# earlgrey register map
Vendor: lowRISC; File version: 0.1
CPU: ibex rev01, little endian, no MPU, no FPU, VTOR, 2 interrupt priority bits, 2 interrupts
Registers are 32-bit, read-write, no defined reset value unless marked. A register's access mark holds for its fields unless they carry their own. Offsets are from the block's base; [hi:lo] are bit positions; {n}, {i} and the like mark numbered series.

## SRAM_CTRL_RET_AON — Interfacing on-chip SRAM blocks with system bus, supports lightweight scrambling, integrity and secure wipe
Base 0x40500000
Same registers: SRAM_CTRL_MAIN 0x411C0000
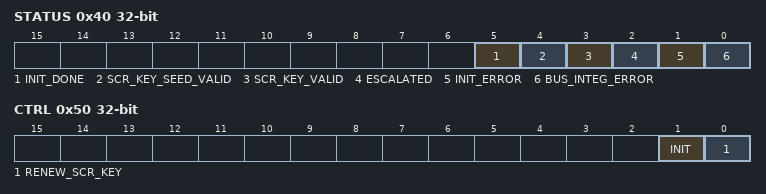
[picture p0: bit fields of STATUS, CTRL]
0x40 STATUS ro — SRAM status register.
  [5] INIT_DONE — Set to 1 if the hardware initialization triggered via !!CTRL.INIT has completed.
  [4] SCR_KEY_SEED_VALID — Set to 1 if the scrambling key has been derived from a valid key seed in OTP.If !!STATUS.SCR_KEY_VALID is set to 1, !!STATUS.SCR_KEY_SEED_VALID should be 1except for cases where the scrambling key seeds have not yet been provisioned toOTP. In such a case, the scrambling key is still ephemeral (i.e., it is derivedusing entropy from CSRNG), but a default all-zero value is used as the key seed.
  [3] SCR_KEY_VALID — Set to 1 if a new scrambling key has been successfully obtained from OTP.Note that if this is set to 0, the SRAM contents are still scrambled, but adefault all-zero key and nonce are used to do so.
  [2] ESCALATED — Set to 1 if the sram controller has received an escalate request.If this is set to 1, the scrambling keys have been reset to the default valuesand all subsequent memory requests will be blocked.This condition is terminal.
  [1] INIT_ERROR — This bit is set to 1 if a the initialization counter has reached an invalid state.This error triggers a fatal_error alert.This condition is terminal.
  [0] BUS_INTEG_ERROR — This bit is set to 1 if a fatal bus integrity fault is detected.This error triggers a fatal_error alert.This condition is terminal.
0x44 EXEC_REGWEN — Lock register for execution enable register.
  [0] Value — When cleared to zero, !!EXEC can not be written anymore.
0x48 EXEC — Sram execution enable.
  [3:0] EN — Write kMultiBitBool4True to this field to enable execution from SRAM.Note that this register only takes effect if the EN_SRAM_IFETCH switchin the OTP HW_CFG partition is set to kMultiBitBool8True. Otherwise executionfrom SRAM cannot be enabled via this register.
0x4C CTRL_REGWEN — Lock register for control register.
  [0] Value — When cleared to zero, !!CTRL can not be written anymore.
0x50 CTRL wo — SRAM ctrl register.
  [1] INIT — Write 1 to request memory init.The init mechanism uses an LFSR that is seeded with a part of the nonce supplied when requesting a scrambling key.Once seeded, the memory is initialized with pseudo-random data pulled from the LFSR.Note that !!CTRL.RENEW_SCR_KEY takes priority when writing 1 to both !!CTRL.RENEW_SCR_KEY and !!CTRL.INIT with the same write transaction.This means that the key request will complete first, followed by SRAM initialization.
  [0] RENEW_SCR_KEY — Write 1 to request a new scrambling key from OTP. After writing to this register, SRAM transactions willbe blocked until !!STATUS.SCR_KEY_VALID has been set to 1. If !!STATUS.SCR_KEY_VALID was already 1before triggering a key renewal, hardware will automatically clear that status bit such that softwarecan poll its status. Note that requesting a new scrambling key takes ~200 OTP cycles, which translatesto ~800 CPU cycles (OTP runs at 24MHz, CPU runs at 100MHz). Note that writing 1 to this register whilea key request is pending has no effect.

## RV_DM — Enables debug support for Ibex, access protected by life cycle
Base 0x41200000
0x100 HALTED wo — Write to this address to acknowledge that the core has halted.
  [0] Value
0x108 GOING wo — Write to this address to acknowledge that the core is executing.
  [0] Value
0x110 RESUMING wo — Write to this address to acknowledge that the core is resuming non-debug operation.
  [0] Value
0x118 EXCEPTION wo — An exception was triggered while the core was in debug mode.
  [0] Value
0x300 WHERETO ro — TODO: No description provided in the spec.
  [31:0] Value
{0x338+4i} ABSTRACTCMD_{i} ro (i=0..9) — TODO: No description provided in the spec.
  [31:0] Value_{i} — Value
{0x360+4i} PROGRAM_BUFFER_{i} ro (i=0..7) — TODO: No description provided in the spec.
  [31:0] Value_{i} — Value
0x380 DATAADDR_0 — TODO: No description provided in the spec.
  [31:0] Value_0 — Value
0x384 DATAADDR_1 — TODO: No description provided in the spec.
  [31:0] Value_1 — Value
{0x400+4i} FLAGS_{i} ro (i=0..255) — TODO: No description provided in the spec.
  [31:0] Value_{i} — Value

## RV_PLIC
Base 0x48000000
{0x40+4i} PRIO{i} (i=0..184) — Interrupt Source {i} Priority
  [1:0] Value
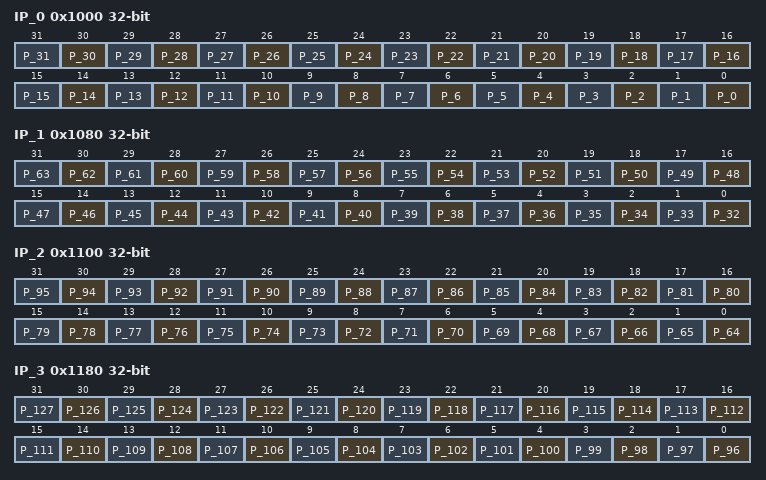
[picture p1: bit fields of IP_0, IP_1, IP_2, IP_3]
0x1000 IP_0 ro — Interrupt Pending
  [n] P_{n} (n=0..31) — Interrupt Pending of Source
0x1080 IP_1 ro — Interrupt Pending
  [n-32] P_{n} (n=32..63) — Interrupt Pending of Source
0x1100 IP_2 ro — Interrupt Pending
  [n-64] P_{n} (n=64..95) — Interrupt Pending of Source
0x1180 IP_3 ro — Interrupt Pending
  [n-96] P_{n} (n=96..127) — Interrupt Pending of Source
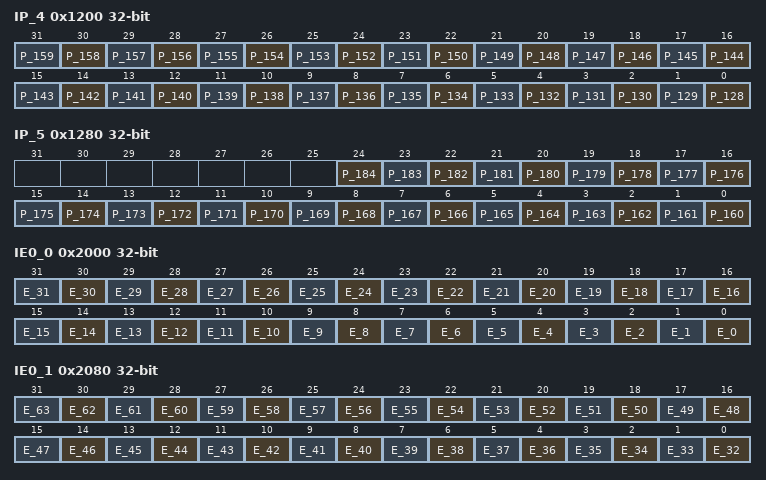
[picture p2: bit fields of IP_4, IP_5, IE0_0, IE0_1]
0x1200 IP_4 ro — Interrupt Pending
  [n-128] P_{n} (n=128..159) — Interrupt Pending of Source
0x1280 IP_5 ro — Interrupt Pending
  [n-160] P_{n} (n=160..184) — Interrupt Pending of Source
0x2000 IE0_0 — Interrupt Enable for Target 0
  [n] E_{n} (n=0..31) — Interrupt Enable of Source
0x2080 IE0_1 — Interrupt Enable for Target 0
  [n-32] E_{n} (n=32..63) — Interrupt Enable of Source
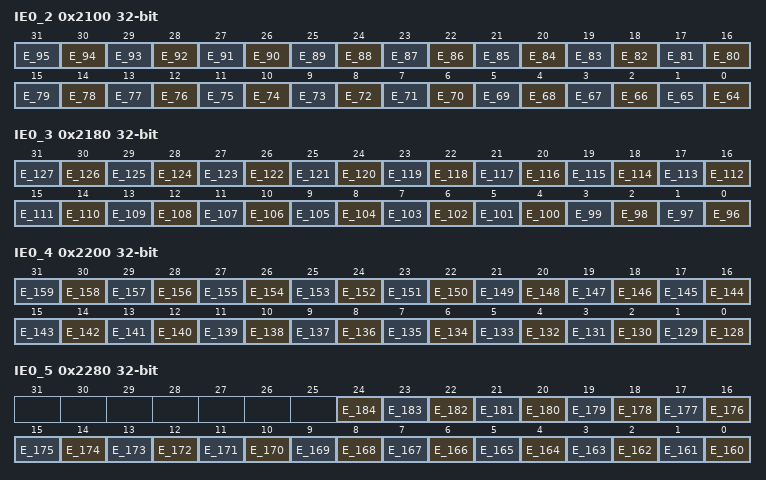
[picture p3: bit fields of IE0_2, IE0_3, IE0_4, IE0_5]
0x2100 IE0_2 — Interrupt Enable for Target 0
  [n-64] E_{n} (n=64..95) — Interrupt Enable of Source
0x2180 IE0_3 — Interrupt Enable for Target 0
  [n-96] E_{n} (n=96..127) — Interrupt Enable of Source
0x2200 IE0_4 — Interrupt Enable for Target 0
  [n-128] E_{n} (n=128..159) — Interrupt Enable of Source
0x2280 IE0_5 — Interrupt Enable for Target 0
  [n-160] E_{n} (n=160..184) — Interrupt Enable of Source
0x200000 THRESHOLD0 — Threshold of priority for Target 0
  [1:0] Value
0x200004 CC0 — Claim interrupt by read, complete interrupt by write for Target 0.Value read/written is interrupt ID. Reading a value of 0 means no pending interrupts.
  [7:0] Value
0x4000000 MSIP0 — msip for Hart 0.Write 1 to here asserts software interrupt for Hart msip_o[0], write 0 to clear.
  [0] Value — Software Interrupt Pending register
0x4004000 ALERT_TEST wo
  [0] fatal_fault — 'Write 1 to trigger one alert event of this kind.'

## ROM_CTRL — Interfaces scrambled boot ROM with system bus and KMAC for initial health check after reset
Base 0x411E0000
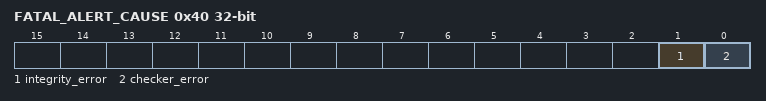
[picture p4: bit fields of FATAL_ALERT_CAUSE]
0x40 FATAL_ALERT_CAUSE ro — The cause of a fatal alert.The bits of this register correspond to errors that can cause a fatalalert. Software can read these bits to see what went wrong. Once set,these bits cannot be cleared.
  [1] integrity_error — Set on an integrity error from the register interface.
  [0] checker_error — Set on a fatal error detected by the ROM checker.
{0x44+4i} DIGEST_{i} ro (i=0..7) — The digest computed from the contents of ROM
  [31:0] DIGEST_{i} — 32 bits of the digest
{0x64+4i} EXP_DIGEST_{i} ro (i=0..7) — The expected digest, stored in the top words of ROM
  [31:0] DIGEST_{i} — 32 bits of the digest
